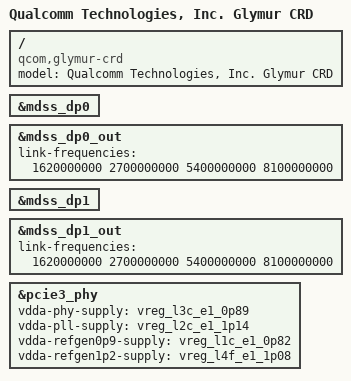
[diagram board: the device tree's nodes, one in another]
// SPDX-License-Identifier: BSD-3-Clause
/*
 * Copyright (c) Qualcomm Technologies, Inc. and/or its subsidiaries.
 */

/dts-v1/;

#include "glymur.dtsi"
#include "glymur-crd.dtsi"

/ {
	model = "Qualcomm Technologies, Inc. Glymur CRD";
	compatible = "qcom,glymur-crd", "qcom,glymur";
};

&mdss_dp0 {
	status = "okay";
};

&mdss_dp0_out {
	link-frequencies = /bits/ 64 <1620000000 2700000000 5400000000 8100000000>;
};

&mdss_dp1 {
	status = "okay";
};

&mdss_dp1_out {
	link-frequencies = /bits/ 64 <1620000000 2700000000 5400000000 8100000000>;
};

&pcie3_phy {
	vdda-phy-supply = <&vreg_l3c_e1_0p89>;
	vdda-pll-supply = <&vreg_l2c_e1_1p14>;

	vdda-refgen0p9-supply = <&vreg_l1c_e1_0p82>;
	vdda-refgen1p2-supply = <&vreg_l4f_e1_1p08>;
};
